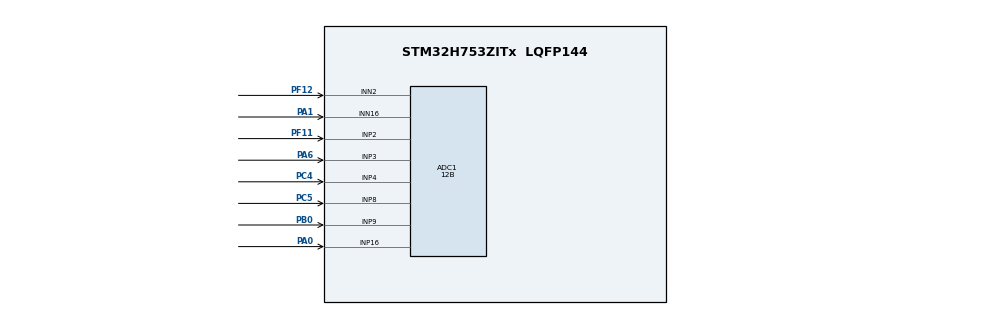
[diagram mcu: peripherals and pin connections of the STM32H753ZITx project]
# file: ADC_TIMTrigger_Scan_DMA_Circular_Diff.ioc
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ADC1.Channel-1\#ChannelRegularConversion=ADC_CHANNEL_2
ADC1.Channel-2\#ChannelRegularConversion=ADC_CHANNEL_3
ADC1.Channel-3\#ChannelRegularConversion=ADC_CHANNEL_4
ADC1.Channel-4\#ChannelRegularConversion=ADC_CHANNEL_8
ADC1.Channel-5\#ChannelRegularConversion=ADC_CHANNEL_9
ADC1.ClockPrescaler=ADC_CLOCK_ASYNC_DIV16
ADC1.ConversionDataManagement=ADC_CONVERSIONDATA_DMA_CIRCULAR
ADC1.DiscontinuousConvMode=DISABLE
ADC1.EOCSelection=ADC_EOC_SEQ_CONV
ADC1.EnableInjectedConversion=ENABLE
ADC1.EnableInjectedOversampling=ENABLE
ADC1.ExternalTrigConv=ADC_EXTERNALTRIG_T2_TRGO
ADC1.InjNumberOfConversion=1
ADC1.InjOversamplingRatio=4
ADC1.InjOversamplingRightShift=ADC_RIGHTBITSHIFT_2
ADC1.InjectedChannel-6\#ChannelInjectedConversion=ADC_CHANNEL_16
ADC1.InjectedOffsetNumber-6\#ChannelInjectedConversion=ADC_OFFSET_NONE
ADC1.InjectedOffsetSaturation-6\#ChannelInjectedConversion=DISABLE
ADC1.InjectedRank-6\#ChannelInjectedConversion=1
ADC1.InjectedSamplingTime-6\#ChannelInjectedConversion=ADC_SAMPLETIME_32CYCLES_5
ADC1.InjectedSingleDiff-6\#ChannelInjectedConversion=ADC_DIFFERENTIAL_ENDED
ADC1.NbrOfConversion=5
ADC1.NbrOfConversionFlag=1
ADC1.OffsetNumber-1\#ChannelRegularConversion=ADC_OFFSET_NONE
ADC1.OffsetNumber-2\#ChannelRegularConversion=ADC_OFFSET_NONE
ADC1.OffsetNumber-3\#ChannelRegularConversion=ADC_OFFSET_NONE
ADC1.OffsetNumber-4\#ChannelRegularConversion=ADC_OFFSET_NONE
ADC1.OffsetNumber-5\#ChannelRegularConversion=ADC_OFFSET_NONE
ADC1.OffsetSignedSaturation-1\#ChannelRegularConversion=DISABLE
ADC1.Overrun=ADC_OVR_DATA_OVERWRITTEN
ADC1.OversamplingMode=ENABLE
ADC1.Rank-1\#ChannelRegularConversion=1
ADC1.Rank-2\#ChannelRegularConversion=2
ADC1.Rank-3\#ChannelRegularConversion=3
ADC1.Rank-4\#ChannelRegularConversion=4
ADC1.Rank-5\#ChannelRegularConversion=5
ADC1.Ratio=8
ADC1.Resolution=ADC_RESOLUTION_12B
ADC1.RightBitShift=ADC_RIGHTBITSHIFT_3
ADC1.SamplingTime-1\#ChannelRegularConversion=ADC_SAMPLETIME_64CYCLES_5
ADC1.SamplingTime-2\#ChannelRegularConversion=ADC_SAMPLETIME_16CYCLES_5
ADC1.SamplingTime-3\#ChannelRegularConversion=ADC_SAMPLETIME_16CYCLES_5
ADC1.SamplingTime-4\#ChannelRegularConversion=ADC_SAMPLETIME_16CYCLES_5
ADC1.SamplingTime-5\#ChannelRegularConversion=ADC_SAMPLETIME_16CYCLES_5
ADC1.SingleDiff-1\#ChannelRegularConversion=ADC_DIFFERENTIAL_ENDED
ADC1.master=1
CORTEX_M7.default_mode_Activation=1
Dma.ADC1.0.Direction=DMA_PERIPH_TO_MEMORY
Dma.ADC1.0.EventEnable=DISABLE
Dma.ADC1.0.FIFOMode=DMA_FIFOMODE_DISABLE
Dma.ADC1.0.Instance=DMA1_Stream0
Dma.ADC1.0.MemDataAlignment=DMA_MDATAALIGN_HALFWORD
Dma.ADC1.0.MemInc=DMA_MINC_ENABLE
Dma.ADC1.0.Mode=DMA_CIRCULAR
Dma.ADC1.0.PeriphDataAlignment=DMA_PDATAALIGN_HALFWORD
Dma.ADC1.0.PeriphInc=DMA_PINC_DISABLE
Dma.ADC1.0.Polarity=HAL_DMAMUX_REQ_GEN_RISING
Dma.ADC1.0.Priority=DMA_PRIORITY_HIGH
Dma.ADC1.0.RequestNumber=1
Dma.ADC1.0.SignalID=NONE
Dma.ADC1.0.SyncEnable=DISABLE
Dma.ADC1.0.SyncPolarity=HAL_DMAMUX_SYNC_NO_EVENT
Dma.ADC1.0.SyncRequestNumber=1
Dma.ADC1.0.SyncSignalID=NONE
Dma.Request0=ADC1
Mcu.Family=STM32H7
Mcu.Name=STM32H753ZITx
Mcu.Package=LQFP144
NVIC.ADC_IRQn=true\:4\:0\:true\:false\:true\:true\:true\:true
NVIC.DMA1_Stream0_IRQn=true\:5\:0\:true\:false\:true\:false\:true\:true
NVIC.PriorityGroup=NVIC_PRIORITYGROUP_4
PA0.Mode=IN16-Differential
PA0.Signal=ADC1_INP16
PA1.Mode=IN16-Differential
PA1.Signal=ADC1_INN16
PA6.Signal=ADCx_INP3
PB0.Signal=ADCx_INP9
PC4.Signal=ADCx_INP4
PC5.Signal=ADCx_INP8
PF11.Mode=IN2-Differential
PF11.Signal=ADC1_INP2
PF12.Mode=IN2-Differential
PF12.Signal=ADC1_INN2
PH0-OSC_IN\ (PH0).Mode=HSE-External-Oscillator
PH0-OSC_IN\ (PH0).Signal=RCC_OSC_IN
PH1-OSC_OUT\ (PH1).Mode=HSE-External-Oscillator
PH1-OSC_OUT\ (PH1).Signal=RCC_OSC_OUT
ProjectManager.HeapSize=0x200
ProjectManager.StackSize=0x400
ProjectManager.TargetToolchain=STM32CubeIDE
RCC.ADCFreq_Value=76000000
RCC.APB1Freq_Value=120000000
RCC.APB2Freq_Value=120000000
RCC.APB3Freq_Value=120000000
RCC.APB4Freq_Value=120000000
RCC.CortexFreq_Value=480000000
RCC.D1PPRE=RCC_APB3_DIV2
RCC.D2PPRE1=RCC_APB1_DIV2
RCC.D2PPRE2=RCC_APB2_DIV2
RCC.D3PPRE=RCC_APB4_DIV2
RCC.DIVM1=1
RCC.DIVM2=1
RCC.DIVN1=120
RCC.DIVN2=19
RCC.HCLKFreq_Value=240000000
RCC.HPRE=RCC_HCLK_DIV2
RCC.HSE_VALUE=8000000
RCC.PLL2FRACN=0
RCC.PLLFRACN=0
RCC.PLLSourceVirtual=RCC_PLLSOURCE_HSE
RCC.SYSCLKFreq_VALUE=480000000
RCC.SYSCLKSource=RCC_SYSCLKSOURCE_PLLCLK
RCC.USBFreq_Value=480000000
SH.ADCx_INP3.0=ADC1_INP3,IN3-Single-Ended
SH.ADCx_INP4.0=ADC1_INP4,IN4-Single-Ended
SH.ADCx_INP8.0=ADC1_INP8,IN8-Single-Ended
SH.ADCx_INP9.0=ADC1_INP9,IN9-Single-Ended
TIM2.Period=999
TIM2.Prescaler=239
TIM2.TIM_MasterOutputTrigger=TIM_TRGO_UPDATE
VP_MEMORYMAP_VS_MEMORYMAP.Mode=CurAppReg
VP_TIM2_VS_ClockSourceINT.Mode=Internal
board=custom

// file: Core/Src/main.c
/* USER CODE BEGIN Header */
/**
  ******************************************************************************
  * @file           : main.c
  * @brief          : Main program body
  ******************************************************************************
  * @attention
  *
  * Copyright (c) 2025 STMicroelectronics.
  * All rights reserved.
  *
  * This software is licensed under terms that can be found in the LICENSE file
  * in the root directory of this software component.
  * If no LICENSE file comes with this software, it is provided AS-IS.
  *
  ******************************************************************************
  */
/* USER CODE END Header */
#include "main.h"
#include "adc.h"
#include "dma.h"
#include "tim.h"
#include "gpio.h"

/* USER CODE BEGIN Includes */
#include "adc_app.h"
/* USER CODE END Includes */

void SystemClock_Config(void);
static void MPU_Config(void);

int main(void)
{

  /* MPU Configuration--------------------------------------------------------*/
  MPU_Config();

  /* MCU Configuration--------------------------------------------------------*/

  /* Reset of all peripherals, Initializes the Flash interface and the Systick. */
  HAL_Init();

  /* Configure the system clock */
  SystemClock_Config();

  /* Initialize all configured peripherals */
  MX_GPIO_Init();
  MX_DMA_Init();
  MX_ADC1_Init();
  MX_TIM2_Init();
  /* USER CODE BEGIN 2 */
  adc_app_init(&hadc1, &htim2);
  adc_app_start();
  /* USER CODE END 2 */

  /* Infinite loop */
  /* USER CODE BEGIN WHILE */

  uint16_t frame[ADC_APP_REG_CH_COUNT];
  uint32_t last_inj_ms = 0;

  while (1)
  {

    // 1) Regular frame handling
    if (adc_app_frame_available()) {
      adc_app_get_latest_frame(frame);

      // Esempio: qui puoi mettere breakpoint e vedere i 5 canali.
      // TODO: processing / scaling / logging
    }

    // 2) Injected trigger every 1000 ms (demo)
    uint32_t now = HAL_GetTick();
    if ((now - last_inj_ms) >= 1000u) {
      last_inj_ms = now;
      (void)adc_app_trigger_injected_it();
    }

    // 3) Injected result
    if (adc_app_injected_available()) {
      int16_t inj = adc_app_get_injected_latest();
      // TODO: use inj value (e.g., store, threshold check, debug print)
    }
    /* USER CODE END WHILE */

  }
}

void SystemClock_Config(void)
{
  RCC_OscInitTypeDef RCC_OscInitStruct = {0};
  RCC_ClkInitTypeDef RCC_ClkInitStruct = {0};

  /** Supply configuration update enable
  */
  HAL_PWREx_ConfigSupply(PWR_LDO_SUPPLY);

  /** Configure the main internal regulator output voltage
  */
  __HAL_PWR_VOLTAGESCALING_CONFIG(PWR_REGULATOR_VOLTAGE_SCALE0);

  while(!__HAL_PWR_GET_FLAG(PWR_FLAG_VOSRDY)) {}

  /** Initializes the RCC Oscillators according to the specified parameters
  * in the RCC_OscInitTypeDef structure.
  */
  RCC_OscInitStruct.OscillatorType = RCC_OSCILLATORTYPE_HSE;
  RCC_OscInitStruct.HSEState = RCC_HSE_ON;
  RCC_OscInitStruct.PLL.PLLState = RCC_PLL_ON;
  RCC_OscInitStruct.PLL.PLLSource = RCC_PLLSOURCE_HSE;
  RCC_OscInitStruct.PLL.PLLM = 1;
  RCC_OscInitStruct.PLL.PLLN = 120;
  RCC_OscInitStruct.PLL.PLLP = 2;
  RCC_OscInitStruct.PLL.PLLQ = 2;
  RCC_OscInitStruct.PLL.PLLR = 2;
  RCC_OscInitStruct.PLL.PLLRGE = RCC_PLL1VCIRANGE_3;
  RCC_OscInitStruct.PLL.PLLVCOSEL = RCC_PLL1VCOWIDE;
  RCC_OscInitStruct.PLL.PLLFRACN = 0;
  if (HAL_RCC_OscConfig(&RCC_OscInitStruct) != HAL_OK)
  {
    Error_Handler();
  }

  /** Initializes the CPU, AHB and APB buses clocks
  */
  RCC_ClkInitStruct.ClockType = RCC_CLOCKTYPE_HCLK|RCC_CLOCKTYPE_SYSCLK
                              |RCC_CLOCKTYPE_PCLK1|RCC_CLOCKTYPE_PCLK2
                              |RCC_CLOCKTYPE_D3PCLK1|RCC_CLOCKTYPE_D1PCLK1;
  RCC_ClkInitStruct.SYSCLKSource = RCC_SYSCLKSOURCE_PLLCLK;
  RCC_ClkInitStruct.SYSCLKDivider = RCC_SYSCLK_DIV1;
  RCC_ClkInitStruct.AHBCLKDivider = RCC_HCLK_DIV2;
  RCC_ClkInitStruct.APB3CLKDivider = RCC_APB3_DIV2;
  RCC_ClkInitStruct.APB1CLKDivider = RCC_APB1_DIV2;
  RCC_ClkInitStruct.APB2CLKDivider = RCC_APB2_DIV2;
  RCC_ClkInitStruct.APB4CLKDivider = RCC_APB4_DIV2;

  if (HAL_RCC_ClockConfig(&RCC_ClkInitStruct, FLASH_LATENCY_4) != HAL_OK)
  {
    Error_Handler();
  }
}

 /* MPU Configuration */

void MPU_Config(void)
{
  MPU_Region_InitTypeDef MPU_InitStruct = {0};

  /* Disables the MPU */
  HAL_MPU_Disable();

  /** Initializes and configures the Region and the memory to be protected
  */
  MPU_InitStruct.Enable = MPU_REGION_ENABLE;
  MPU_InitStruct.Number = MPU_REGION_NUMBER0;
  MPU_InitStruct.BaseAddress = 0x0;
  MPU_InitStruct.Size = MPU_REGION_SIZE_4GB;
  MPU_InitStruct.SubRegionDisable = 0x87;
  MPU_InitStruct.TypeExtField = MPU_TEX_LEVEL0;
  MPU_InitStruct.AccessPermission = MPU_REGION_NO_ACCESS;
  MPU_InitStruct.DisableExec = MPU_INSTRUCTION_ACCESS_DISABLE;
  MPU_InitStruct.IsShareable = MPU_ACCESS_SHAREABLE;
  MPU_InitStruct.IsCacheable = MPU_ACCESS_NOT_CACHEABLE;
  MPU_InitStruct.IsBufferable = MPU_ACCESS_NOT_BUFFERABLE;

  HAL_MPU_ConfigRegion(&MPU_InitStruct);
  /* Enables the MPU */
  HAL_MPU_Enable(MPU_PRIVILEGED_DEFAULT);

}

void Error_Handler(void)
{
  __disable_irq();
  while (1)
  {
  }
}
